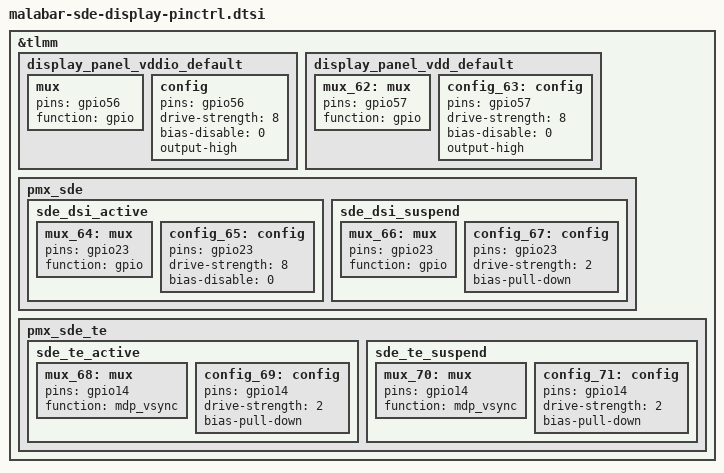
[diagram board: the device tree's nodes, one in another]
// SPDX-License-Identifier: BSD-3-Clause
/*
 * Copyright (c) Qualcomm Technologies, Inc. and/or its subsidiaries.
 */

&tlmm {
	display_panel_vddio_default: display_panel_vddio_default {
		mux: mux {
			pins = "gpio56";
			function = "gpio";
		};

		config: config {
			pins = "gpio56";
			drive-strength = <8>;
			bias-disable = <0>;
			output-high;
		};
	};

	display_panel_vdd_default: display_panel_vdd_default {
		mux_62: mux {
			pins = "gpio57";
			function = "gpio";
		};

		config_63: config {
			pins = "gpio57";
			drive-strength = <8>;
			bias-disable = <0>;
			output-high;
		};
	};

	pmx_sde: pmx_sde {
		sde_dsi_active: sde_dsi_active {
			mux_64: mux {
				pins = "gpio23";
				function = "gpio";
			};

			config_65: config {
				pins = "gpio23";
				drive-strength = <8>;   /* 8 mA */
				bias-disable = <0>;   /* no pull */
			};
		};

		sde_dsi_suspend: sde_dsi_suspend {
			mux_66: mux {
				pins = "gpio23";
				function = "gpio";
			};

			config_67: config {
				pins = "gpio23";
				drive-strength = <2>;   /* 2 mA */
				bias-pull-down;         /* PULL DOWN */
			};
		};
	};

	pmx_sde_te: pmx_sde_te {
		sde_te_active: sde_te_active {
			mux_68: mux {
				pins = "gpio14";
				function = "mdp_vsync";
			};

			config_69: config {
				pins = "gpio14";
				drive-strength = <2>;   /* 2 mA */
				bias-pull-down;         /* PULL DOWN */
			};
		};

		sde_te_suspend: sde_te_suspend {
			mux_70: mux {
				pins = "gpio14";
				function = "mdp_vsync";
			};

			config_71: config {
				pins = "gpio14";
				drive-strength = <2>;   /* 2 mA */
				bias-pull-down;         /* PULL DOWN */
			};
		};
	};
};
